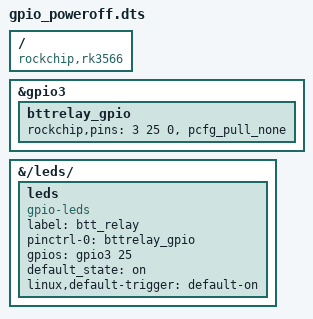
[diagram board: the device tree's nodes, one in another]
/dts-v1/;
/plugin/;

/ {

    compatible = "rockchip,rk3566";


    fragment@0 {
        target = <&gpio3>;
        __overlay__ {
                bttrelay_gpio: bttrelay_gpio {
                        rockchip,pins = <3 25 0 &pcfg_pull_none>;
                };

            };
        };
    

    fragment@1 {
        target-path = "/leds/";
        __overlay__ {
                leds: leds {
                        compatible = "gpio-leds";
                        label = "btt_relay";
                        pinctrl-names = "default";
                        pinctrl-0 =<&bttrelay_gpio>;

                        gpios = <&gpio3 25 0>;
                        default_state="on";
                        linux,default-trigger = "default-on";
                };
        };
    };
};
